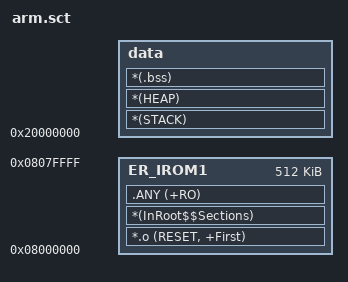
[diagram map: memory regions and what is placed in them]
; *************************************************************
; *** Scatter-Loading Description File generated by uVision ***
; *************************************************************

LR_IROM1 0x08000000 0x00080000  {    ; load region size_region
  ER_IROM1 0x08000000 0x00080000  {  ; load address = execution address
   *.o (RESET, +First)
   *(InRoot$$Sections)
   .ANY (+RO)
  }
  data 0x20000000 { ; .data
   *(.data)
  }
  armboot_cmd + 0 { ; .armboot_cmd : command set address
   *(armboot_cmd)
  }
  bss + 0 { ; .bss
   *(STACK)
   *(HEAP)
   *(.bss)
  }
}

